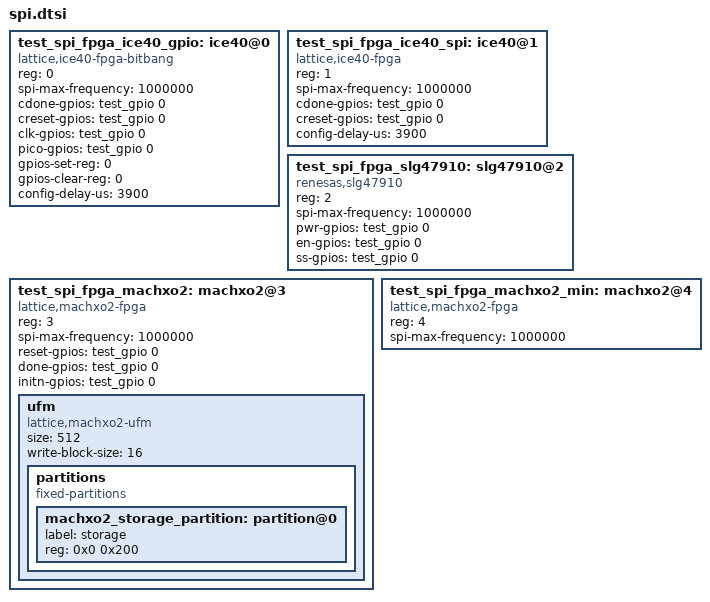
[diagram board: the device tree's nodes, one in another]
/*
 * Copyright (c) 2020, Linaro Ltd.
 *
 * SPDX-License-Identifier: Apache-2.0
 *
 * Application overlay for spi devices
 */

test_spi_fpga_ice40_gpio: ice40@0 {
	compatible = "lattice,ice40-fpga-bitbang";

	reg = <0>;
	spi-max-frequency = <1000000>;

	cdone-gpios = <&test_gpio 0 0>;
	creset-gpios = <&test_gpio 0 0>;
	clk-gpios = <&test_gpio 0 0>;
	pico-gpios = <&test_gpio 0 0>;
	gpios-set-reg = <0>;
	gpios-clear-reg = <0>;
	config-delay-us = <3900>;
	status = "okay";
};

test_spi_fpga_ice40_spi: ice40@1 {
	compatible = "lattice,ice40-fpga";

	reg = <1>;
	spi-max-frequency = <1000000>;

	cdone-gpios = <&test_gpio 0 0>;
	creset-gpios = <&test_gpio 0 0>;
	config-delay-us = <3900>;
	status = "okay";
};

test_spi_fpga_slg47910: slg47910@2 {
	compatible = "renesas,slg47910";

	reg = <2>;
	spi-max-frequency = <1000000>;

	pwr-gpios = <&test_gpio 0 0>;
	en-gpios = <&test_gpio 0 0>;
	ss-gpios = <&test_gpio 0 0>;
	status = "okay";
};

test_spi_fpga_machxo2: machxo2@3 {
	compatible = "lattice,machxo2-fpga";

	reg = <3>;
	spi-max-frequency = <1000000>;

	reset-gpios = <&test_gpio 0 0>;
	done-gpios = <&test_gpio 0 0>;
	initn-gpios = <&test_gpio 0 0>;
	status = "okay";

	ufm: ufm {
		compatible = "lattice,machxo2-ufm";
		size = <512>;
		write-block-size = <16>;

		partitions {
			compatible = "fixed-partitions";
			#address-cells = <1>;
			#size-cells = <1>;

			/* The UFM has one erase sector; only a full-size partition is erasable. */
			machxo2_storage_partition: partition@0 {
				label = "storage";
				reg = <0x0 0x200>;
			};
		};
	};
};

test_spi_fpga_machxo2_min: machxo2@4 {
	compatible = "lattice,machxo2-fpga";

	reg = <4>;
	spi-max-frequency = <1000000>;
	status = "okay";
};
